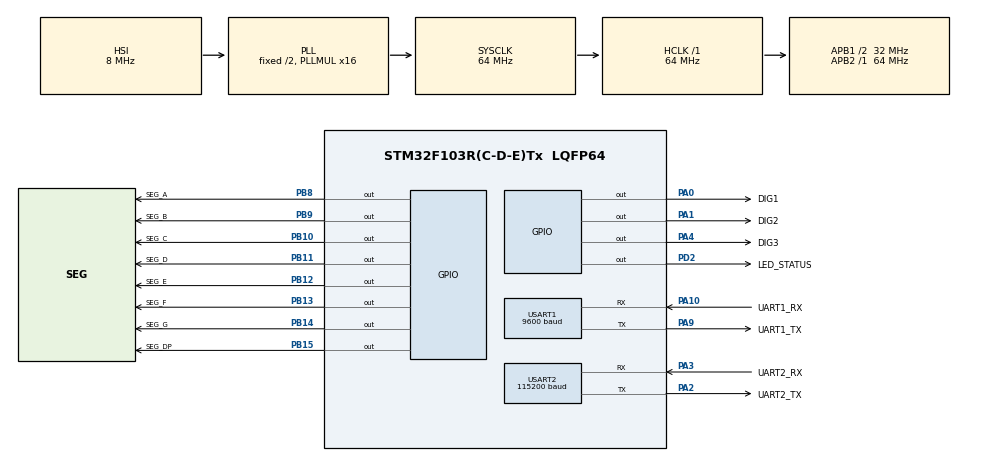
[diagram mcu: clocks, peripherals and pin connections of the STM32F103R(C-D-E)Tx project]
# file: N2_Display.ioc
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Mcu.Family=STM32F1
Mcu.Name=STM32F103R(C-D-E)Tx
Mcu.Package=LQFP64
NVIC.PriorityGroup=NVIC_PRIORITYGROUP_4
NVIC.TIM3_IRQn=true\:1\:0\:false\:false\:true\:true\:true\:true
NVIC.USART1_IRQn=true\:2\:0\:false\:false\:true\:true\:true\:true
NVIC.USART2_IRQn=true\:2\:0\:false\:false\:true\:true\:true\:true
PA0-WKUP.GPIO_Label=DIG1
PA0-WKUP.GPIO_ModeDefaultOutputPP=GPIO_MODE_OUTPUT_PP
PA0-WKUP.GPIO_PuPd=GPIO_NOPULL
PA0-WKUP.GPIO_Speed=GPIO_SPEED_FREQ_LOW
PA0-WKUP.PinState=GPIO_PIN_RESET
PA0-WKUP.Signal=GPIO_Output
PA1.GPIO_Label=DIG2
PA1.GPIO_ModeDefaultOutputPP=GPIO_MODE_OUTPUT_PP
PA1.GPIO_PuPd=GPIO_NOPULL
PA1.GPIO_Speed=GPIO_SPEED_FREQ_LOW
PA1.PinState=GPIO_PIN_RESET
PA1.Signal=GPIO_Output
PA10.GPIO_Label=UART1_RX
PA10.Mode=Asynchronous
PA10.Signal=USART1_RX
PA13.Mode=Serial_Wire
PA13.Signal=SYS_JTMS-SWDIO
PA14.Mode=Serial_Wire
PA14.Signal=SYS_JTCK-SWCLK
PA2.GPIO_Label=UART2_TX
PA2.Mode=Asynchronous
PA2.Signal=USART2_TX
PA3.GPIO_Label=UART2_RX
PA3.Mode=Asynchronous
PA3.Signal=USART2_RX
PA4.GPIO_Label=DIG3
PA4.GPIO_ModeDefaultOutputPP=GPIO_MODE_OUTPUT_PP
PA4.GPIO_PuPd=GPIO_NOPULL
PA4.GPIO_Speed=GPIO_SPEED_FREQ_LOW
PA4.PinState=GPIO_PIN_RESET
PA4.Signal=GPIO_Output
PA9.GPIO_Label=UART1_TX
PA9.Mode=Asynchronous
PA9.Signal=USART1_TX
PB10.GPIO_Label=SEG_C
PB10.GPIO_ModeDefaultOutputPP=GPIO_MODE_OUTPUT_PP
PB10.GPIO_PuPd=GPIO_NOPULL
PB10.GPIO_Speed=GPIO_SPEED_FREQ_LOW
PB10.PinState=GPIO_PIN_RESET
PB10.Signal=GPIO_Output
PB11.GPIO_Label=SEG_D
PB11.GPIO_ModeDefaultOutputPP=GPIO_MODE_OUTPUT_PP
PB11.GPIO_PuPd=GPIO_NOPULL
PB11.GPIO_Speed=GPIO_SPEED_FREQ_LOW
PB11.PinState=GPIO_PIN_RESET
PB11.Signal=GPIO_Output
PB12.GPIO_Label=SEG_E
PB12.GPIO_ModeDefaultOutputPP=GPIO_MODE_OUTPUT_PP
PB12.GPIO_PuPd=GPIO_NOPULL
PB12.GPIO_Speed=GPIO_SPEED_FREQ_LOW
PB12.PinState=GPIO_PIN_RESET
PB12.Signal=GPIO_Output
PB13.GPIO_Label=SEG_F
PB13.GPIO_ModeDefaultOutputPP=GPIO_MODE_OUTPUT_PP
PB13.GPIO_PuPd=GPIO_NOPULL
PB13.GPIO_Speed=GPIO_SPEED_FREQ_LOW
PB13.PinState=GPIO_PIN_RESET
PB13.Signal=GPIO_Output
PB14.GPIO_Label=SEG_G
PB14.GPIO_ModeDefaultOutputPP=GPIO_MODE_OUTPUT_PP
PB14.GPIO_PuPd=GPIO_NOPULL
PB14.GPIO_Speed=GPIO_SPEED_FREQ_LOW
PB14.PinState=GPIO_PIN_RESET
PB14.Signal=GPIO_Output
PB15.GPIO_Label=SEG_DP
PB15.GPIO_ModeDefaultOutputPP=GPIO_MODE_OUTPUT_PP
PB15.GPIO_PuPd=GPIO_NOPULL
PB15.GPIO_Speed=GPIO_SPEED_FREQ_LOW
PB15.PinState=GPIO_PIN_RESET
PB15.Signal=GPIO_Output
PB8.GPIO_Label=SEG_A
PB8.GPIO_ModeDefaultOutputPP=GPIO_MODE_OUTPUT_PP
PB8.GPIO_PuPd=GPIO_NOPULL
PB8.GPIO_Speed=GPIO_SPEED_FREQ_LOW
PB8.PinState=GPIO_PIN_RESET
PB8.Signal=GPIO_Output
PB9.GPIO_Label=SEG_B
PB9.GPIO_ModeDefaultOutputPP=GPIO_MODE_OUTPUT_PP
PB9.GPIO_PuPd=GPIO_NOPULL
PB9.GPIO_Speed=GPIO_SPEED_FREQ_LOW
PB9.PinState=GPIO_PIN_RESET
PB9.Signal=GPIO_Output
PD2.GPIO_Label=LED_STATUS
PD2.GPIO_ModeDefaultOutputPP=GPIO_MODE_OUTPUT_PP
PD2.GPIO_PuPd=GPIO_NOPULL
PD2.GPIO_Speed=GPIO_SPEED_FREQ_LOW
PD2.PinState=GPIO_PIN_RESET
PD2.Signal=GPIO_Output
ProjectManager.HeapSize=0x200
ProjectManager.StackSize=0x800
ProjectManager.TargetToolchain=MDK-ARM V5.32
RCC.ADCPresc=RCC_ADCPCLK2_DIV6
RCC.AHBFreq_Value=64000000
RCC.APB1CLKDivider=RCC_HCLK_DIV2
RCC.APB1Freq_Value=32000000
RCC.APB1TimFreq_Value=64000000
RCC.APB2Freq_Value=64000000
RCC.APB2TimFreq_Value=64000000
RCC.HCLKFreq_Value=64000000
RCC.HSI_VALUE=8000000
RCC.PLLMUL=RCC_PLL_MUL16
RCC.PLLSourceVirtual=RCC_PLLSOURCE_HSI_DIV2
RCC.SYSCLKFreq_VALUE=64000000
RCC.SYSCLKSource=RCC_SYSCLKSOURCE_PLLCLK
TIM3.Period=999
TIM3.Prescaler=63
USART1.BaudRate=9600
USART1.VirtualMode=VM_ASYNC
USART2.BaudRate=115200
USART2.VirtualMode=VM_ASYNC
VP_TIM3_VS_ClockSourceINT.Mode=Internal
board=custom

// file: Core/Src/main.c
/* USER CODE BEGIN Header */
/**
  ******************************************************************************
  * @file           : main.c
  * @brief          : Main program body
  ******************************************************************************
  * @attention
  *
  * Copyright (c) 2026 STMicroelectronics.
  * All rights reserved.
  *
  * This software is licensed under terms that can be found in the LICENSE file
  * in the root directory of this software component.
  * If no LICENSE file comes with this software, it is provided AS-IS.
  *
  ******************************************************************************
  */
/* USER CODE END Header */
#include "main.h"
#include "tim.h"
#include "usart.h"
#include "gpio.h"

/* USER CODE BEGIN Includes */
#include "app_n2.h"
/* USER CODE END Includes */

void SystemClock_Config(void);

int main(void)
{

  /* MCU Configuration--------------------------------------------------------*/

  /* Reset of all peripherals, Initializes the Flash interface and the Systick. */
  HAL_Init();

  /* Configure the system clock */
  SystemClock_Config();

  /* Initialize all configured peripherals */
  MX_GPIO_Init();
  MX_USART1_UART_Init();
  MX_USART2_UART_Init();
  MX_TIM3_Init();
  /* USER CODE BEGIN 2 */
  App_N2_Init();
  /* USER CODE END 2 */

  /* Infinite loop */
  while (1)
  {

    /* USER CODE BEGIN 3 */
    App_N2_Task();
    HAL_Delay(1U);
  }
  /* USER CODE END 3 */
}

void SystemClock_Config(void)
{
  RCC_OscInitTypeDef RCC_OscInitStruct = {0};
  RCC_ClkInitTypeDef RCC_ClkInitStruct = {0};

  /** Initializes the RCC Oscillators according to the specified parameters
  * in the RCC_OscInitTypeDef structure.
  */
  RCC_OscInitStruct.OscillatorType = RCC_OSCILLATORTYPE_HSI;
  RCC_OscInitStruct.HSIState = RCC_HSI_ON;
  RCC_OscInitStruct.HSICalibrationValue = RCC_HSICALIBRATION_DEFAULT;
  RCC_OscInitStruct.PLL.PLLState = RCC_PLL_ON;
  RCC_OscInitStruct.PLL.PLLSource = RCC_PLLSOURCE_HSI_DIV2;
  RCC_OscInitStruct.PLL.PLLMUL = RCC_PLL_MUL16;
  if (HAL_RCC_OscConfig(&RCC_OscInitStruct) != HAL_OK)
  {
    Error_Handler();
  }

  /** Initializes the CPU, AHB and APB buses clocks
  */
  RCC_ClkInitStruct.ClockType = RCC_CLOCKTYPE_HCLK|RCC_CLOCKTYPE_SYSCLK
                              |RCC_CLOCKTYPE_PCLK1|RCC_CLOCKTYPE_PCLK2;
  RCC_ClkInitStruct.SYSCLKSource = RCC_SYSCLKSOURCE_PLLCLK;
  RCC_ClkInitStruct.AHBCLKDivider = RCC_SYSCLK_DIV1;
  RCC_ClkInitStruct.APB1CLKDivider = RCC_HCLK_DIV2;
  RCC_ClkInitStruct.APB2CLKDivider = RCC_HCLK_DIV1;

  if (HAL_RCC_ClockConfig(&RCC_ClkInitStruct, FLASH_LATENCY_2) != HAL_OK)
  {
    Error_Handler();
  }
}

void Error_Handler(void)
{
  __disable_irq();
  while (1)
  {
  }
}
